# ECM3531 register map
Vendor: EtaCompute; Series: ECM35xx; File version: 1.0.0
CPU: CM3 r1p1, little endian, MPU, no FPU, 3 interrupt priority bits
Registers are 32-bit, read-write, reset 0x0 unless marked. A register's access mark holds for its fields unless they carry their own. Offsets are from the block's base; [hi:lo] are bit positions; {n}, {i} and the like mark numbered series; 'fields as' and 'values as' point back to an identical list.

## GPIO8 — The General Purpose I/O (GPIO) Device provides programmable access to the pins of the chip.
Base 0x50030000
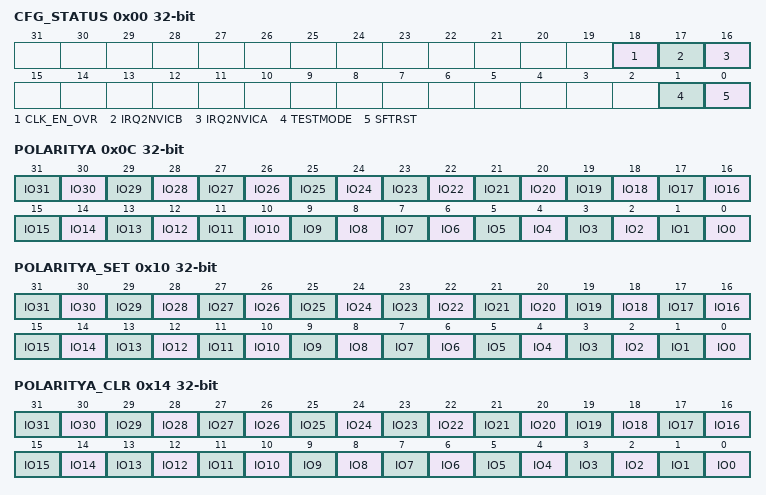
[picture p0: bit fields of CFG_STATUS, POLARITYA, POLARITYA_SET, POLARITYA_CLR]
0x00 CFG_STATUS — Configuration and status bits for the GPIO register.
  [18] CLK_EN_OVR — Force the clock enable for this module ON to prevent clock gating at the HFO. Intended for debug purposes.
    1=ENABLE (Prevent HFO clock gating.); 0=DISABLE (Allow HFO clock gating when block is inactive.)
  [17] IRQ2NVICB ro — Provides a read only view of what the GPIO device is sending to the NVIC on either interrupt 1.
  [16] IRQ2NVICA ro — Provides a read only view of what the GPIO device is sending to the NVIC on either interrupt 0.
  [1] TESTMODE — Set to 1 to enable test bus outputs instead of GPIO[31:16] outputs. The default state is to make test bus outputs available. Set to 0 to disable test bus and use GPIO.
    1=ENABLE (Enable test mode outputs and disable GPIO outputs.); 0=DISABLE (Disable test mode outputs and enable GPIO outputs.)
  [0] SFTRST — Write a one to this bit to soft reset the GPIO8 block.
    1=RESET (Perform a soft reset on just this block)
0x04 DEBUG0_READ_ONLY — Provide a read only value for diagnostics.
  [31:0] VALUE ro — Debug Read Only Value for Diagnostics.
0x08 DEBUG1_READ_ONLY — Provide a read only value for diagnostics.
  [31:0] VALUE ro — Debug Read Only Value for Diagnostics.
0x0C POLARITYA — Polarity register for the GPIO A interrupt
  [n] IO{n} wo (n=0..31) — 0 - active high interrupt, 1 - active low interrupt
0x10 POLARITYA_SET — Set Polarity bits for GPIO Interrupt A
  [n] IO{n} wo (n=0..31) — Set to 1 to set polarity A bit
0x14 POLARITYA_CLR — Clear Polarity bits for GPIO Interrupt A
  [n] IO{n} wo (n=0..31) — Set to 1 to clear polarity A bit
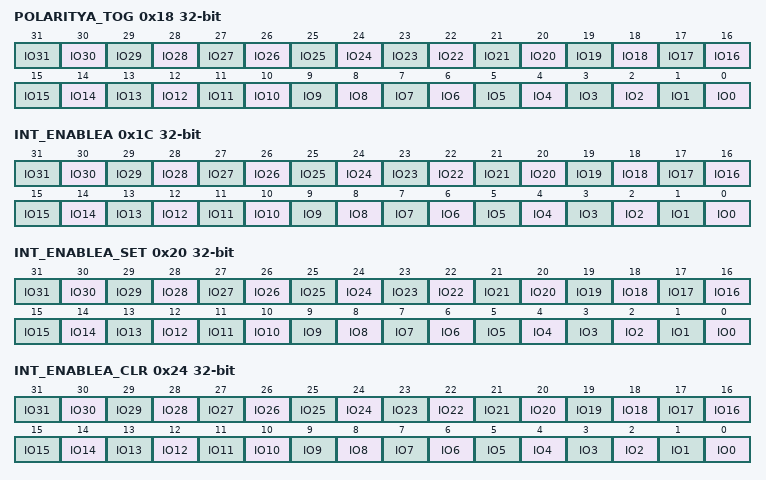
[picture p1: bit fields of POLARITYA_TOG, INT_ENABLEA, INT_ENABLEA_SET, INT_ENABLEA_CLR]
0x18 POLARITYA_TOG — Toggle Polarity bits for GPIO Interrupt A
  [n] IO{n} wo (n=0..31) — Set to 1 toggle polarity A bit
0x1C INT_ENABLEA — Interrupt Enable register for the GPIO A interrupt
  [n] IO{n} wo (n=0..31) — Set to 1 to enable interrupt A bit
0x20 INT_ENABLEA_SET — Set Interrupt Enable bits for GPIO Interrupt A
  [n] IO{n} wo (n=0..31) — Set to 1 to enable interrupt A bit
0x24 INT_ENABLEA_CLR — Set Interrupt Enable bits for GPIO Interrupt A
  [n] IO{n} wo (n=0..31) — Set to 1 to disable interrupt A bit
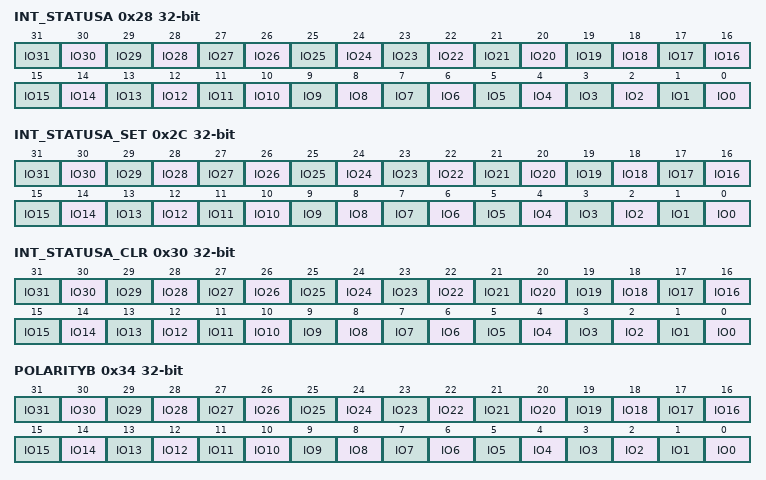
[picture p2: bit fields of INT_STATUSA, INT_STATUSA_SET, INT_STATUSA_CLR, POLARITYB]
0x28 INT_STATUSA — Interrupt Enable register for the GPIO A interrupt
  [n] IO{n} (n=0..31) — Set to 1 to set interrupt status bit
0x2C INT_STATUSA_SET — Set Interrupt Status bits for GPIO Interrupt A
  [n] IO{n} (n=0..31) — Set to 1 to set interrupt status bit
0x30 INT_STATUSA_CLR — Clear Interrupt Status bits for GPIO Interrupt A
  [n] IO{n} wo (n=0..31) — Set to 1 to clear interrupt status bit
0x34 POLARITYB — Polarity register for the GPIO A interrupt.
  fields as POLARITYA
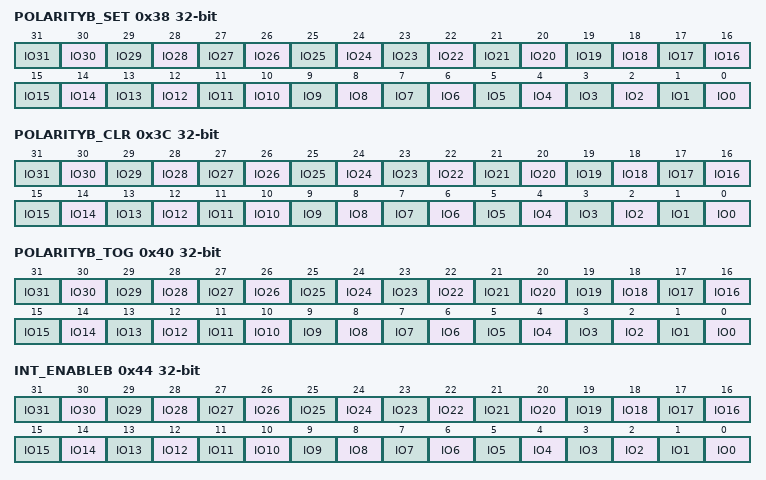
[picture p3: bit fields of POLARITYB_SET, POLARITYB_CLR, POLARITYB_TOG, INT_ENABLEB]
0x38 POLARITYB_SET — Set Polarity bits for GPIO Interrupt B
  fields as POLARITYA
0x3C POLARITYB_CLR — Clear Polarity bits for GPIO Interrupt B
  [n] IO{n} wo (n=0..31) — Set to 1 to clear polarity B bit
0x40 POLARITYB_TOG — Toggle Polarity bits for GPIO Interrupt B
  [n] IO{n} wo (n=0..31) — Set to 1 toggle polarity B bit
0x44 INT_ENABLEB — Interrupt Enable register for the GPIO B interrupt.
  [n] IO{n} wo (n=0..31) — Set to 1 to enable interrupt B bit
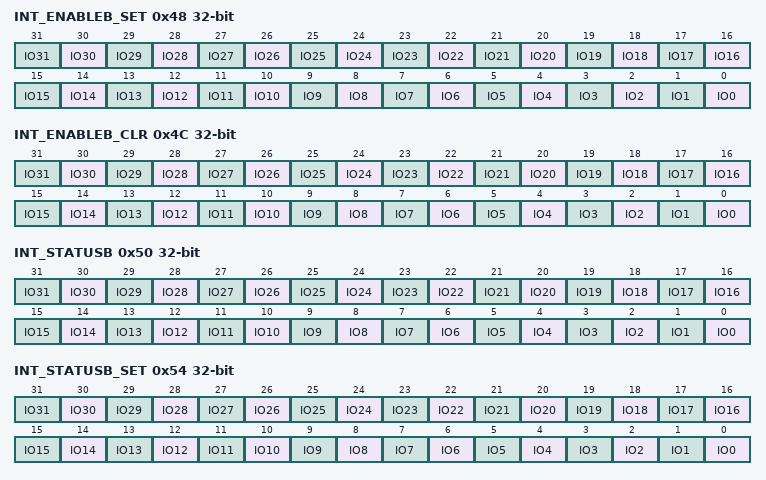
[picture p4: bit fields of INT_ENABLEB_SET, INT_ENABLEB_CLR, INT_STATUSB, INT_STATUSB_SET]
0x48 INT_ENABLEB_SET — Set Interrupt Enable bits for GPIO Interrupt B
  [n] IO{n} wo (n=0..31) — Set to 1 to enable interrupt B bit
0x4C INT_ENABLEB_CLR — Set Interrupt Enable bits for GPIO Interrupt B
  [n] IO{n} wo (n=0..31) — Set to 1 to disable interrupt B bit
0x50 INT_STATUSB — Interrupt Enable register for the GPIO B interrupt.
  [n] IO{n} (n=0..31) — Set to 1 to set interrupt status bit
0x54 INT_STATUSB_SET — Set Interrupt Status bits for GPIO Interrupt B
  [n] IO{n} (n=0..31) — Set to 1 to set interrupt status bit
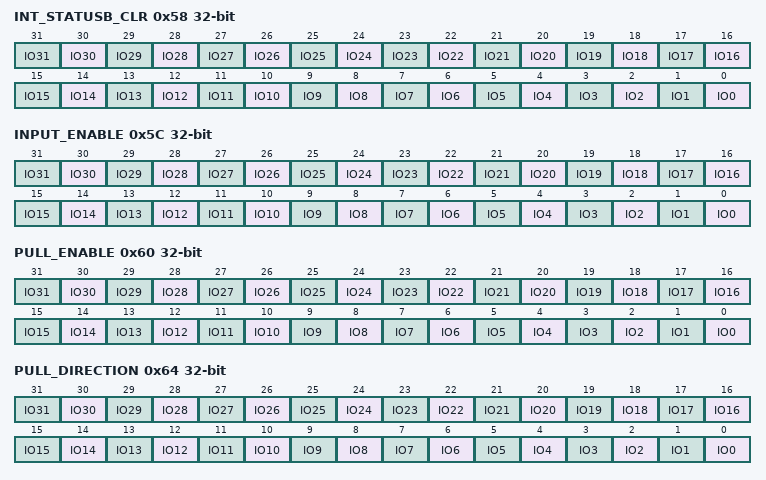
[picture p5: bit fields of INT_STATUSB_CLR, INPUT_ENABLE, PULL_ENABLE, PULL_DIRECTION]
0x58 INT_STATUSB_CLR — Clear Interrupt Status bits for GPIO Interrupt B
  [n] IO{n} wo (n=0..31) — Set to 1 to clear interrupt status bit
0x5C INPUT_ENABLE — Input Enable register for the GPIO.
  [n] IO{n} (n=0..31) — Set to 1 to enable input from a GPIO PAD
0x60 PULL_ENABLE — Pull Up or Down Resistor Enable register for the GPIO. The PADs have 2 resistors in them. One for pulling up and one for pulling down. Bits in this register enable a resistor in the corresponding pad. Which resistor (up or down) is selected in the IO_GPIO8_PULL_DIRECTION register.
  [n] IO{n} (n=0..31) — Set to 1 to enable the pull up or down register in the GPIO PAD
0x64 PULL_DIRECTION — Pull Up or Down Enable register for the GPIO. NOTE: Use IO_GPIO8_PULL_ENABLE to actually turn on the resistor in the pad.
  [n] IO{n} (n=0..31) — 1 - pull-up, 0 - pull-down
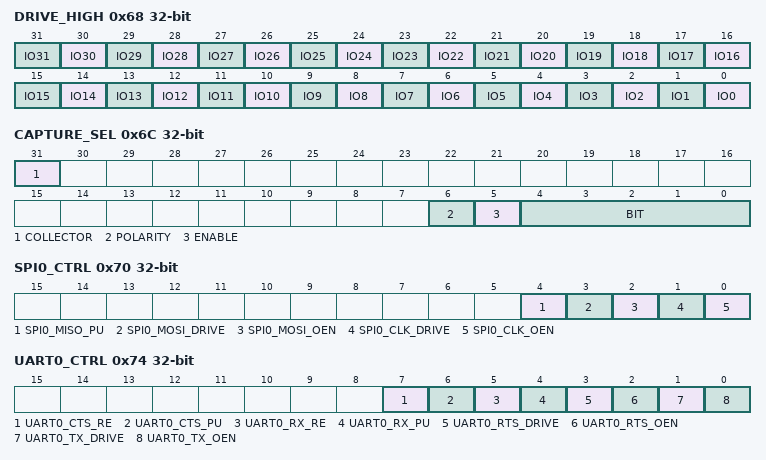
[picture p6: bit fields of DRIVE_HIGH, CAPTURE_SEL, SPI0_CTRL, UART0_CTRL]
0x68 DRIVE_HIGH — High Drive Strength Enable register for the GPIO.
  [n] IO{n} (n=0..31) — 1 - high drive strength, 0 - normal drive strength
0x6C CAPTURE_SEL — This register selects which single GPIO bit is forwarded to the TIMER to capture the current TOD when the bit changes state. It also has a polarity selection for this bit.
  [31] COLLECTOR ro — Provide a read only debug view of internal signals.
  [6] POLARITY — Set to one to invert the polarity of the selected bit before forwarding it.
  [5] ENABLE — Set to one to enable forwarding one GPIO input to the timer.
  [4:0] BIT — Set to one of 0 thru 31, inclusive, to select one GPIO input bit to forward to the TIMER block.
0x70 SPI0_CTRL — This register controls various pad functions for SPI0_CLK, SPI0_MOSI and SPI0_MISO. Unless otherwise stated, these pins affect these pads in any padmux configuration.
  [4] SPI0_MISO_PU — If 0, SPI0_MISO has no pull up enabled. Set to 1 to enable the weak internal pull up.
  [3] SPI0_MOSI_DRIVE — If 0, SPI0_MOSI drive strength is normal. Set to 1 for high drive strength.
  [2] SPI0_MOSI_OEN — If 0, SPI0_MOSI is an output. If 1, SPI0_MOSI is tristated for low power. Note this has no effect in modes where SPI0_MOSI is I2C0_SDA
  [1] SPI0_CLK_DRIVE — If 0, SPI0_CLK drive strength is normal. Set to 1 for high drive strength.
  [0] SPI0_CLK_OEN — If 0, SPI0_CLK is an output. If 1, SPI0_CLK is tristated for low power. Note this has no effect in modes where SPI0_CLK is I2C0_SCL
0x74 UART0_CTRL — This register controls various pad functions for UART0_RX, UART0_TX, UART0_CTS and UART0_RTS. Unless otherwise stated, these pins affect these pads in any padmux configuration.
  [7] UART0_CTS_RE — If 0, UART0_CTS has no pull up or pull down enabled. Set to 1 to enable the weak internal pull up or pull down.
  [6] UART0_CTS_PU — If UART0_CTS_RE is clear, this bit has no effect. If UART0_CTS_RE is set, then this bit selects if the pull is high (1) or if it is low (0).
  [5] UART0_RX_RE — If 0, UART0_RX has no pull up or pull down enabled. Set to 1 to enable the weak internal pull up or pull down.
  [4] UART0_RX_PU — If UART0_RX_RE is clear, this bit has no effect. If UART0_RX_RE is set, then this bit selects if the pull is high (1) or if it is low (0).
  [3] UART0_RTS_DRIVE — If 0, UART0_RTS drive strength is normal. Set to 1 for high drive strength.
  [2] UART0_RTS_OEN — If 0, UART0_RTS is an output. If 1, UART0_RTS is tristated for low power.
  [1] UART0_TX_DRIVE — If 0, UART0_TX drive strength is normal. Set to 1 for high drive strength.
  [0] UART0_TX_OEN — If 0, UART0_TX is an output. If 1, UART0_TX is tristated for low power.
